# STM32G473 register map
File version: 2.8
CPU: CM4 r0p1, little endian, MPU, FPU, 4 interrupt priority bits
Registers are 32-bit, read-write, reset 0x0 unless marked. A register's access mark holds for its fields unless they carry their own. Offsets are from the block's base; [hi:lo] are bit positions.

## TIM6 — Basic-timers
Base 0x40001000
Same registers: TIM7 0x40001400
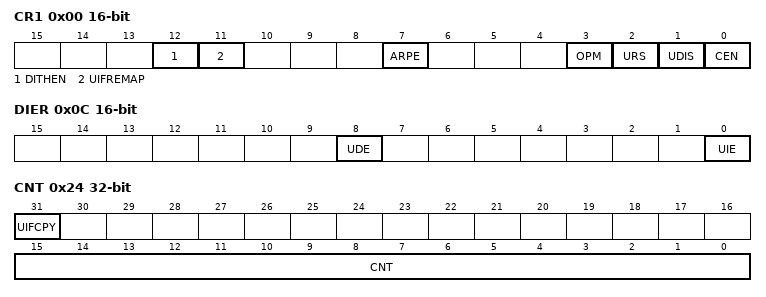
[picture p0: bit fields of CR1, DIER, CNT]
0x00 CR1 16-bit — TIM6 control register 1
  [12] DITHEN — Dithering enable
    0=Disabled (Dithering disabled); 1=Enabled (Dithering enabled)
  [11] UIFREMAP — UIF status bit remapping
    0=Disabled (No remapping. UIF status bit is not copied to TIMx_CNT register bit 31); 1=Enabled (Remapping enabled. UIF status bit is copied to TIMx_CNT register bit 31)
  [7] ARPE — Auto-reload preload enable
    0=Disabled (TIMx_APRR register is not buffered); 1=Enabled (TIMx_APRR register is buffered)
  [3] OPM — One-pulse mode
    0=Disabled (Counter is not stopped at update event); 1=Enabled (Counter stops counting at the next update event (clearing the CEN bit))
  [2] URS — Update request source
    0=AnyEvent (Any of counter overflow/underflow, setting UG, or update through slave mode, generates an update interrupt or DMA request); 1=CounterOnly (Only counter overflow/underflow generates an update interrupt or DMA request)
  [1] UDIS — Update disable
    0=Enabled (Update event enabled); 1=Disabled (Update event disabled)
  [0] CEN — Counter enable
    0=Disabled (Counter disabled); 1=Enabled (Counter enabled)
0x04 CR2 16-bit — TIM6 control register 2
  [6:4] MMS — Master mode selection
    0=Reset (Use UG bit from TIMx_EGR register); 1=Enable (Use CNT bit from TIMx_CEN register); 2=Update (Use the update event)
0x0C DIER 16-bit — TIM6 DMA/Interrupt enable register
  [8] UDE — Update DMA request enable
    0=Disabled (Update DMA request disabled); 1=Enabled (Update DMA request enabled)
  [0] UIE — Update interrupt enable
    0=Disabled (Update interrupt disabled); 1=Enabled (Update interrupt enabled)
0x10 SR 16-bit — TIM6 status register
  [0] UIF write-0-clears — Update interrupt flag
    on read: 0=NoUpdateOccurred; 1=UpdatePending (Update interrupt pending) | on write: 0=Clear flag
0x14 EGR 16-bit wo — TIM6 event generation register
  [0] UG — Update generation
    1=Update (Re-initializes the timer counter and generates an update of the registers.)
0x24 CNT — TIM6 counter
  [31] UIFCPY ro — UIF copy
    0=NoUpdateOccurred; 1=UpdatePending (Update interrupt pending)
  [15:0] CNT — Counter value
0x28 PSC 16-bit — TIM6 prescaler
  [15:0] PSC — Prescaler value
0x2C ARR reset 0xFFFF — TIM6 auto-reload register
  [19:0] ARR — Auto-reload value

## VREFBUF — Voltage reference buffer
Base 0x40010030
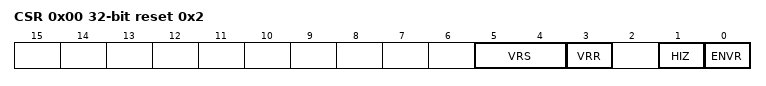
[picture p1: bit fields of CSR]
0x00 CSR access per field reset 0x2 — VREF_BUF Control and Status Register
  [5:4] VRS rw — Voltage reference scale
  [3] VRR ro — Voltage reference buffer ready
  [1] HIZ rw — High impedence mode for the VREF_BUF
  [0] ENVR rw — Enable Voltage Reference
0x04 CCR — VREF_BUF Calibration Control Register
  [5:0] TRIM — Trimming code

## WWDG — System window watchdog
Base 0x40002C00
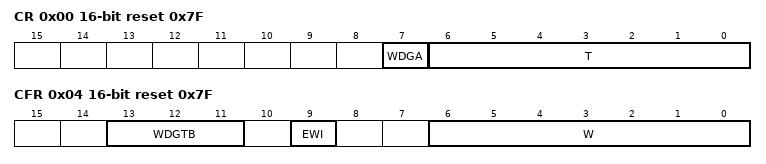
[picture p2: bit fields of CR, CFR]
0x00 CR 16-bit reset 0x7F — Control register
  [7] WDGA — Activation bit
    0=Disabled (Watchdog disabled); 1=Enabled (Watchdog enabled)
  [6:0] T — 7-bit counter (MSB to LSB)
0x04 CFR 16-bit reset 0x7F — Configuration register
  [13:11] WDGTB — Timer base
    0=Div1 (Counter clock (PCLK1 div 4096) div 1); 1=Div2 (Counter clock (PCLK1 div 4096) div 2); 2=Div4 (Counter clock (PCLK1 div 4096) div 4); 3=Div8 (Counter clock (PCLK1 div 4096) div 8); 4=Div16 (Counter clock (PCLK1 div 4096) div 16); 5=Div32 (Counter clock (PCLK1 div 4096) div 32); 6=Div64 (Counter clock (PCLK1 div 4096) div 64); 7=Div128 (Counter clock (PCLK1 div 4096) div 128)
  [9] EWI — Early wakeup interrupt
    on write: 1=Enable (interrupt occurs whenever the counter reaches the value 0x40)
  [6:0] W — 7-bit window value
0x08 SR 16-bit — Status register
  [0] EWIF write-0-clears — Early wakeup interrupt flag
    on read: 0=Finished (The EWI Interrupt Service Routine has been serviced); 1=Pending (The EWI Interrupt Service Routine has been triggered) | on write: 0=Finished (The EWI Interrupt Service Routine has been serviced)
